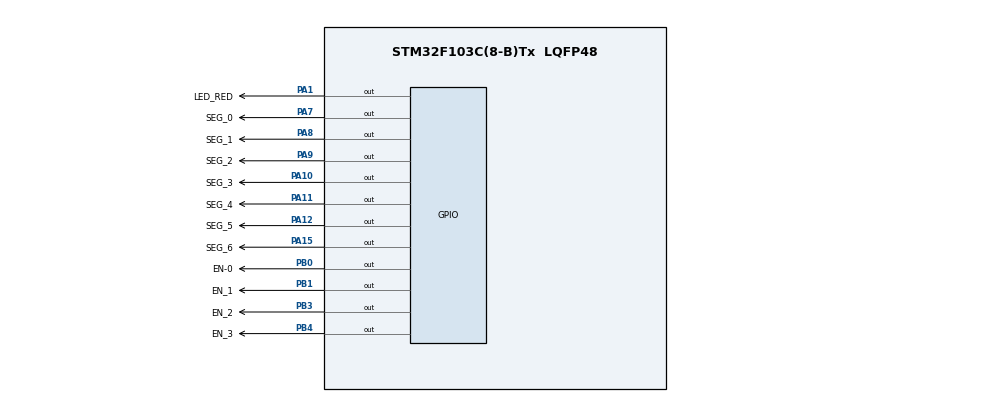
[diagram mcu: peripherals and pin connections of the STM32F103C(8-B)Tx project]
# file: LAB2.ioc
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Mcu.Family=STM32F1
Mcu.Name=STM32F103C(8-B)Tx
Mcu.Package=LQFP48
NVIC.PriorityGroup=NVIC_PRIORITYGROUP_4
NVIC.TIM1_UP_IRQn=true\:0\:0\:false\:false\:true\:true\:true
PA1.GPIO_Label=LED_RED
PA1.Signal=GPIO_Output
PA10.GPIO_Label=SEG_3
PA10.Signal=GPIO_Output
PA11.GPIO_Label=SEG_4
PA11.Signal=GPIO_Output
PA12.GPIO_Label=SEG_5
PA12.Signal=GPIO_Output
PA15.GPIO_Label=SEG_6
PA15.Signal=GPIO_Output
PA7.GPIO_Label=SEG_0
PA7.Signal=GPIO_Output
PA8.GPIO_Label=SEG_1
PA8.Signal=GPIO_Output
PA9.GPIO_Label=SEG_2
PA9.Signal=GPIO_Output
PB0.GPIO_Label=EN-0
PB0.Signal=GPIO_Output
PB1.GPIO_Label=EN_1
PB1.Signal=GPIO_Output
PB3.GPIO_Label=EN_2
PB3.Signal=GPIO_Output
PB4.GPIO_Label=EN_3
PB4.Signal=GPIO_Output
ProjectManager.HeapSize=0x200
ProjectManager.StackSize=0x400
ProjectManager.TargetToolchain=STM32CubeIDE
RCC.APB1Freq_Value=8000000
RCC.APB2Freq_Value=8000000
TIM1.Period=9
TIM1.Prescaler=7999
VP_SYS_VS_ND.Mode=No_Debug
VP_TIM1_VS_ClockSourceINT.Mode=Internal
board=custom

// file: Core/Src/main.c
/* USER CODE BEGIN Header */
/**
  ******************************************************************************
  * @file           : main.c
  * @brief          : Main program body
  ******************************************************************************
  * @attention
  *
  * <h2><center>&copy; Copyright (c) 2024 STMicroelectronics.
  * All rights reserved.</center></h2>
  *
  * This software component is licensed by ST under BSD 3-Clause license,
  * the "License"; You may not use this file except in compliance with the
  * License. You may obtain a copy of the License at:
  *                        opensource.org/licenses/BSD-3-Clause
  *
  ******************************************************************************
  */
/* USER CODE END Header */
#include "main.h"

/* USER CODE BEGIN Includes */
#include "software_timer.h"
#include "display7SEG.h"
/* USER CODE END Includes */

TIM_HandleTypeDef htim1;

void SystemClock_Config(void);
static void MX_TIM1_Init(void);
static void MX_GPIO_Init(void);

int main(void)
{

  /* MCU Configuration--------------------------------------------------------*/

  /* Reset of all peripherals, Initializes the Flash interface and the Systick. */
  HAL_Init();

  /* Configure the system clock */
  SystemClock_Config();

  /* Initialize all configured peripherals */
  MX_TIM1_Init();
  MX_GPIO_Init();
  /* USER CODE BEGIN 2 */
HAL_TIM_Base_Start_IT(&htim1);
setTimer1(100);
int timer_state = 0;
  /* USER CODE END 2 */
  /* Infinite loop */
  while (1)
  {
	  if (timer1_flag == 1){
		  setTimer1(100);
		  // TODO
		  timer_state ++;
		  switch (timer_state){
		  case 1:
			  HAL_GPIO_WritePin(EN_0_GPIO_Port, EN_0_Pin, RESET);
			  HAL_GPIO_WritePin(EN_1_GPIO_Port, EN_1_Pin, SET);
			  HAL_GPIO_WritePin(EN_2_GPIO_Port, EN_2_Pin, SET);
			  HAL_GPIO_WritePin(EN_3_GPIO_Port, EN_3_Pin, SET);
			  display7SEG(1);
			  break;
		  case 2:
			  HAL_GPIO_WritePin(EN_0_GPIO_Port, EN_0_Pin, SET);
			  HAL_GPIO_WritePin(EN_1_GPIO_Port, EN_1_Pin, RESET);
			  HAL_GPIO_WritePin(EN_2_GPIO_Port, EN_2_Pin, SET);
			  HAL_GPIO_WritePin(EN_3_GPIO_Port, EN_3_Pin, SET);
			  display7SEG(2);
			  break;
		  case 3:
			  HAL_GPIO_WritePin(EN_0_GPIO_Port, EN_0_Pin, SET);
			  HAL_GPIO_WritePin(EN_1_GPIO_Port, EN_1_Pin, SET);
			  HAL_GPIO_WritePin(EN_2_GPIO_Port, EN_2_Pin, RESET);
			  HAL_GPIO_WritePin(EN_3_GPIO_Port, EN_3_Pin, SET);
			  display7SEG(3);
			  break;
		  case 4:
			  HAL_GPIO_WritePin(EN_0_GPIO_Port, EN_0_Pin, SET);
			  HAL_GPIO_WritePin(EN_1_GPIO_Port, EN_1_Pin, SET);
			  HAL_GPIO_WritePin(EN_2_GPIO_Port, EN_2_Pin, SET);
			  HAL_GPIO_WritePin(EN_3_GPIO_Port, EN_3_Pin, RESET);
			  display7SEG(0);
			  timer_state = 0;
			  break;
		  }
	  }
  /* USER CODE END 3 */
}
}
void SystemClock_Config(void)
{
  RCC_OscInitTypeDef RCC_OscInitStruct = {0};
  RCC_ClkInitTypeDef RCC_ClkInitStruct = {0};

  /** Initializes the RCC Oscillators according to the specified parameters
  * in the RCC_OscInitTypeDef structure.
  */
  RCC_OscInitStruct.OscillatorType = RCC_OSCILLATORTYPE_HSI;
  RCC_OscInitStruct.HSIState = RCC_HSI_ON;
  RCC_OscInitStruct.HSICalibrationValue = RCC_HSICALIBRATION_DEFAULT;
  RCC_OscInitStruct.PLL.PLLState = RCC_PLL_NONE;
  if (HAL_RCC_OscConfig(&RCC_OscInitStruct) != HAL_OK)
  {
    Error_Handler();
  }
  /** Initializes the CPU, AHB and APB buses clocks
  */
  RCC_ClkInitStruct.ClockType = RCC_CLOCKTYPE_HCLK|RCC_CLOCKTYPE_SYSCLK
                              |RCC_CLOCKTYPE_PCLK1|RCC_CLOCKTYPE_PCLK2;
  RCC_ClkInitStruct.SYSCLKSource = RCC_SYSCLKSOURCE_HSI;
  RCC_ClkInitStruct.AHBCLKDivider = RCC_SYSCLK_DIV1;
  RCC_ClkInitStruct.APB1CLKDivider = RCC_HCLK_DIV1;
  RCC_ClkInitStruct.APB2CLKDivider = RCC_HCLK_DIV1;

  if (HAL_RCC_ClockConfig(&RCC_ClkInitStruct, FLASH_LATENCY_0) != HAL_OK)
  {
    Error_Handler();
  }
}

static void MX_TIM1_Init(void)
{

  TIM_ClockConfigTypeDef sClockSourceConfig = {0};
  TIM_MasterConfigTypeDef sMasterConfig = {0};

  htim1.Instance = TIM1;
  htim1.Init.Prescaler = 7999;
  htim1.Init.CounterMode = TIM_COUNTERMODE_UP;
  htim1.Init.Period = 9;
  htim1.Init.ClockDivision = TIM_CLOCKDIVISION_DIV1;
  htim1.Init.RepetitionCounter = 0;
  htim1.Init.AutoReloadPreload = TIM_AUTORELOAD_PRELOAD_DISABLE;
  if (HAL_TIM_Base_Init(&htim1) != HAL_OK)
  {
    Error_Handler();
  }
  sClockSourceConfig.ClockSource = TIM_CLOCKSOURCE_INTERNAL;
  if (HAL_TIM_ConfigClockSource(&htim1, &sClockSourceConfig) != HAL_OK)
  {
    Error_Handler();
  }
  sMasterConfig.MasterOutputTrigger = TIM_TRGO_RESET;
  sMasterConfig.MasterSlaveMode = TIM_MASTERSLAVEMODE_DISABLE;
  if (HAL_TIMEx_MasterConfigSynchronization(&htim1, &sMasterConfig) != HAL_OK)
  {
    Error_Handler();
  }

}

static void MX_GPIO_Init(void)
{
  GPIO_InitTypeDef GPIO_InitStruct = {0};

  /* GPIO Ports Clock Enable */
  __HAL_RCC_GPIOA_CLK_ENABLE();
  __HAL_RCC_GPIOB_CLK_ENABLE();

  /*Configure GPIO pin Output Level */
  HAL_GPIO_WritePin(GPIOA, LED_RED_Pin|SEG_0_Pin|SEG_1_Pin|SEG_2_Pin
                          |SEG_3_Pin|SEG_4_Pin|SEG_5_Pin|SEG_6_Pin, GPIO_PIN_RESET);

  /*Configure GPIO pin Output Level */
  HAL_GPIO_WritePin(GPIOB, EN_0_Pin|EN_1_Pin|EN_2_Pin|EN_3_Pin, GPIO_PIN_RESET);

  /*Configure GPIO pins : LED_RED_Pin SEG_0_Pin SEG_1_Pin SEG_2_Pin
                           SEG_3_Pin SEG_4_Pin SEG_5_Pin SEG_6_Pin */
  GPIO_InitStruct.Pin = LED_RED_Pin|SEG_0_Pin|SEG_1_Pin|SEG_2_Pin
                          |SEG_3_Pin|SEG_4_Pin|SEG_5_Pin|SEG_6_Pin;
  GPIO_InitStruct.Mode = GPIO_MODE_OUTPUT_PP;
  GPIO_InitStruct.Pull = GPIO_NOPULL;
  GPIO_InitStruct.Speed = GPIO_SPEED_FREQ_LOW;
  HAL_GPIO_Init(GPIOA, &GPIO_InitStruct);

  /*Configure GPIO pins : EN_0_Pin EN_1_Pin EN_2_Pin EN_3_Pin */
  GPIO_InitStruct.Pin = EN_0_Pin|EN_1_Pin|EN_2_Pin|EN_3_Pin;
  GPIO_InitStruct.Mode = GPIO_MODE_OUTPUT_PP;
  GPIO_InitStruct.Pull = GPIO_NOPULL;
  GPIO_InitStruct.Speed = GPIO_SPEED_FREQ_LOW;
  HAL_GPIO_Init(GPIOB, &GPIO_InitStruct);

}

/* USER CODE BEGIN 4 */
int counter = 200;
void HAL_TIM_PeriodElapsedCallback(TIM_HandleTypeDef *htim){
		timerRun();
}
/* USER CODE END 4 */

void Error_Handler(void)
{
  __disable_irq();
  while (1)
  {
  }
}

/************************ (C) COPYRIGHT STMicroelectronics *****END OF FILE****/
